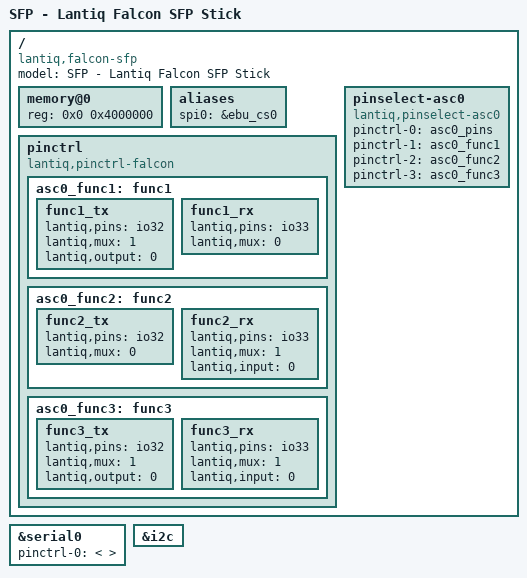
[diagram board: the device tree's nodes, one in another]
/dts-v1/;

/include/ "falcon.dtsi"
/include/ "falcon_sflash.dtsi"

/ {
	model = "SFP - Lantiq Falcon SFP Stick";
	compatible = "lantiq,falcon-sfp", "lantiq,falcon";
	
	memory@0 {
		device_type = "memory";
		reg = <0x0 0x4000000>;
	};
	
	aliases {
		spi0 = &ebu_cs0;
	};
	
	pinctrl {
		compatible = "lantiq,pinctrl-falcon";

		asc0_func1: func1 {
			func1_tx {
				lantiq,pins = "io32";
				lantiq,mux = <1>;
				lantiq,output = <0>;
			};
			
			func1_rx {
				lantiq,pins = "io33";
				lantiq,mux = <0>;
			};
		};
		
		asc0_func2: func2 {
			func2_tx {
				lantiq,pins = "io32";
				lantiq,mux = <0>;
			};
			
			func2_rx {
				lantiq,pins = "io33";
				lantiq,mux = <1>;
				lantiq,input = <0>;
			};
		};
		
		asc0_func3: func3 {
			func3_tx {
				lantiq,pins = "io32";
				lantiq,mux = <1>;
				lantiq,output = <0>;
			};
			
			func3_rx {
				lantiq,pins = "io33";
				lantiq,mux = <1>;
				lantiq,input = <0>;
			};
		};
	};

	pinselect-asc0 {
		compatible = "lantiq,pinselect-asc0";
		pinctrl-names = "asc0", "func1", "func2", "func3";
		pinctrl-0 = <&asc0_pins>;
		pinctrl-1 = <&asc0_func1>;
		pinctrl-2 = <&asc0_func2>;
		pinctrl-3 = <&asc0_func3>;
	};
};

&serial0 {
	pinctrl-names = "default";
	pinctrl-0 = < >;
};

&i2c {
	status = "okay";
};
